AUTOSAR XML (schema 4-0-3)
package /ECU_Abstractions
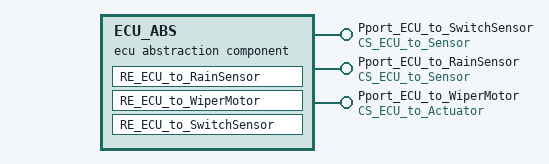
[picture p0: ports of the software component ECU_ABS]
  ecu abstraction sw component type ECU_ABS
    provide port Pport_ECU_to_SwitchSensor: provided-interface=CS_ECU_to_Sensor
    provide port Pport_ECU_to_RainSensor: provided-interface=CS_ECU_to_Sensor
    provide port Pport_ECU_to_WiperMotor: provided-interface=CS_ECU_to_Actuator
    behavior IB_ECU_ABS
      operation invoked event OIE_ECU_to_WiperSensor: start-on-event=IB_ECU_ABS/RE_ECU_to_RainSensor, operation=Pport_ECU_to_RainSensor.CS_Oper_ECU_to_RainSensor
      operation invoked event OIE_ECU_to_SwitchSensor: start-on-event=RE_ECU_to_SwitchSensor, operation=Pport_ECU_to_SwitchSensor.CS_Oper_ECU_to_SwitchSensor
      operation invoked event OIE_ECU_to_Wipermotor: start-on-event=RE_ECU_to_WiperMotor, operation=Pport_ECU_to_WiperMotor.CS_Oper_ECU_to_WiperMotor
      runnable RE_ECU_to_RainSensor
      runnable RE_ECU_to_WiperMotor
      runnable RE_ECU_to_SwitchSensor
package /Applications
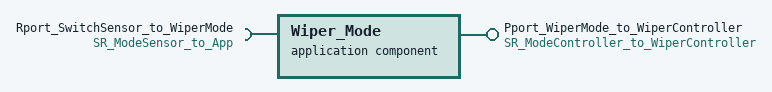
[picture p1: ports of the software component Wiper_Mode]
  application sw component type Wiper_Mode
    require port Rport_SwitchSensor_to_WiperMode: required-interface=SR_ModeSensor_to_App
    provide port Pport_WiperMode_to_WiperController: provided-interface=SR_ModeController_to_WiperController
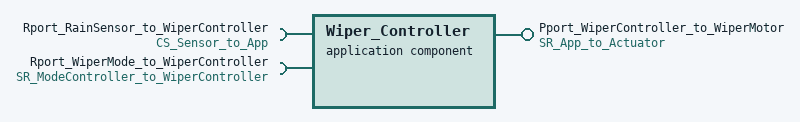
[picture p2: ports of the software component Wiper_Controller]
  application sw component type Wiper_Controller
    require port Rport_RainSensor_to_WiperController: required-interface=CS_Sensor_to_App
    provide port Pport_WiperController_to_WiperMotor: provided-interface=SR_App_to_Actuator
    require port Rport_WiperMode_to_WiperController: required-interface=SR_ModeController_to_WiperController
package /Sensors_and_Actuators
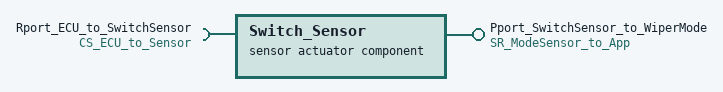
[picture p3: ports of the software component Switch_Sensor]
  sensor actuator sw component type Switch_Sensor
    require port Rport_ECU_to_SwitchSensor: required-interface=CS_ECU_to_Sensor
    provide port Pport_SwitchSensor_to_WiperMode: provided-interface=SR_ModeSensor_to_App
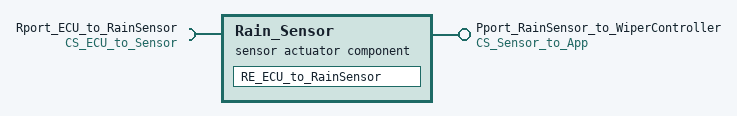
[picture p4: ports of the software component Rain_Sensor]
  sensor actuator sw component type Rain_Sensor
    require port Rport_ECU_to_RainSensor: required-interface=CS_ECU_to_Sensor
    provide port Pport_RainSensor_to_WiperController: provided-interface=CS_Sensor_to_App
    behavior IB_Rain_Sensor
      runnable RE_ECU_to_RainSensor: symbol=RE_ECU_to_Rainsensor
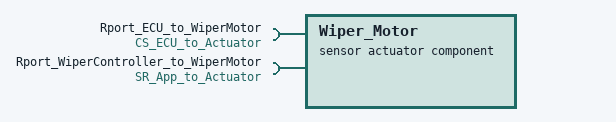
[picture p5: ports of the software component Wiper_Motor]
  sensor actuator sw component type Wiper_Motor
    require port Rport_ECU_to_WiperMotor: required-interface=CS_ECU_to_Actuator
    require port Rport_WiperController_to_WiperMotor: required-interface=SR_App_to_Actuator
